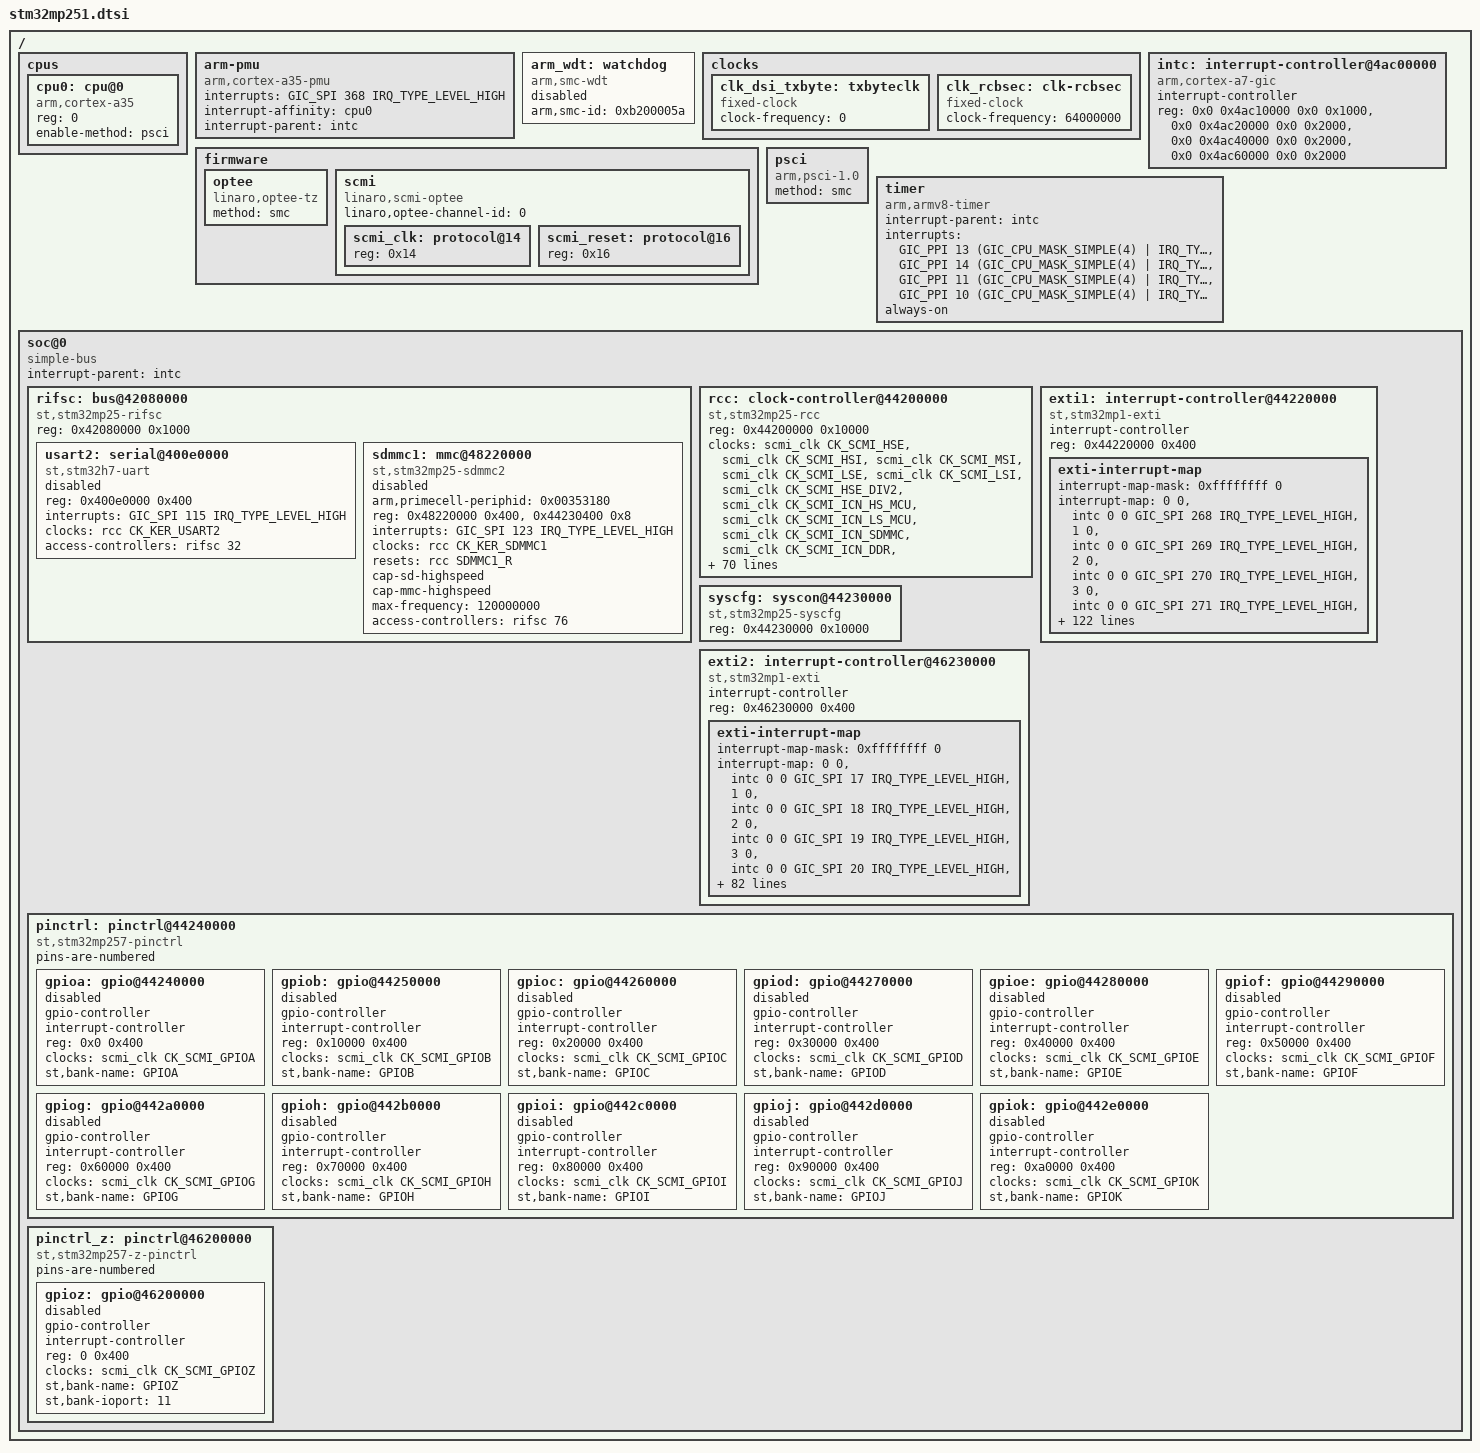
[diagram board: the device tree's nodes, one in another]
// SPDX-License-Identifier: (GPL-2.0-or-later OR BSD-3-Clause)
/*
 * Copyright (C) STMicroelectronics 2023 - All Rights Reserved
 * Author: Alexandre Torgue <alexandre.torgue@foss.st.com> for STMicroelectronics.
 */
#include <dt-bindings/clock/st,stm32mp25-rcc.h>
#include <dt-bindings/interrupt-controller/arm-gic.h>
#include <dt-bindings/reset/st,stm32mp25-rcc.h>

/ {
	#address-cells = <2>;
	#size-cells = <2>;

	cpus {
		#address-cells = <1>;
		#size-cells = <0>;

		cpu0: cpu@0 {
			compatible = "arm,cortex-a35";
			device_type = "cpu";
			reg = <0>;
			enable-method = "psci";
		};
	};

	arm-pmu {
		compatible = "arm,cortex-a35-pmu";
		interrupts = <GIC_SPI 368 IRQ_TYPE_LEVEL_HIGH>;
		interrupt-affinity = <&cpu0>;
		interrupt-parent = <&intc>;
	};

	arm_wdt: watchdog {
		compatible = "arm,smc-wdt";
		arm,smc-id = <0xb200005a>;
		status = "disabled";
	};

	clocks {
		clk_dsi_txbyte: txbyteclk {
			#clock-cells = <0>;
			compatible = "fixed-clock";
			clock-frequency = <0>;
		};

		clk_rcbsec: clk-rcbsec {
			#clock-cells = <0>;
			compatible = "fixed-clock";
			clock-frequency = <64000000>;
		};
	};

	firmware {
		optee {
			compatible = "linaro,optee-tz";
			method = "smc";
		};

		scmi {
			compatible = "linaro,scmi-optee";
			#address-cells = <1>;
			#size-cells = <0>;
			linaro,optee-channel-id = <0>;

			scmi_clk: protocol@14 {
				reg = <0x14>;
				#clock-cells = <1>;
			};

			scmi_reset: protocol@16 {
				reg = <0x16>;
				#reset-cells = <1>;
			};
		};
	};

	intc: interrupt-controller@4ac00000 {
		compatible = "arm,cortex-a7-gic";
		#interrupt-cells = <3>;
		#address-cells = <1>;
		interrupt-controller;
		reg = <0x0 0x4ac10000 0x0 0x1000>,
		      <0x0 0x4ac20000 0x0 0x2000>,
		      <0x0 0x4ac40000 0x0 0x2000>,
		      <0x0 0x4ac60000 0x0 0x2000>;
	};

	psci {
		compatible = "arm,psci-1.0";
		method = "smc";
	};

	timer {
		compatible = "arm,armv8-timer";
		interrupt-parent = <&intc>;
		interrupts = <GIC_PPI 13 (GIC_CPU_MASK_SIMPLE(4) | IRQ_TYPE_LEVEL_LOW)>,
			     <GIC_PPI 14 (GIC_CPU_MASK_SIMPLE(4) | IRQ_TYPE_LEVEL_LOW)>,
			     <GIC_PPI 11 (GIC_CPU_MASK_SIMPLE(4) | IRQ_TYPE_LEVEL_LOW)>,
			     <GIC_PPI 10 (GIC_CPU_MASK_SIMPLE(4) | IRQ_TYPE_LEVEL_LOW)>;
		always-on;
	};

	soc@0 {
		compatible = "simple-bus";
		#address-cells = <1>;
		#size-cells = <1>;
		interrupt-parent = <&intc>;
		ranges = <0x0 0x0 0x0 0x80000000>;

		rifsc: bus@42080000 {
			compatible = "st,stm32mp25-rifsc", "simple-bus";
			reg = <0x42080000 0x1000>;
			#address-cells = <1>;
			#size-cells = <1>;
			#access-controller-cells = <1>;
			ranges;

			usart2: serial@400e0000 {
				compatible = "st,stm32h7-uart";
				reg = <0x400e0000 0x400>;
				interrupts = <GIC_SPI 115 IRQ_TYPE_LEVEL_HIGH>;
				clocks = <&rcc CK_KER_USART2>;
				access-controllers = <&rifsc 32>;
				status = "disabled";
			};

			sdmmc1: mmc@48220000 {
				compatible = "st,stm32mp25-sdmmc2", "arm,pl18x", "arm,primecell";
				arm,primecell-periphid = <0x00353180>;
				reg = <0x48220000 0x400>, <0x44230400 0x8>;
				interrupts = <GIC_SPI 123 IRQ_TYPE_LEVEL_HIGH>;
				clocks = <&rcc CK_KER_SDMMC1>;
				clock-names = "apb_pclk";
				resets = <&rcc SDMMC1_R>;
				cap-sd-highspeed;
				cap-mmc-highspeed;
				max-frequency = <120000000>;
				access-controllers = <&rifsc 76>;
				status = "disabled";
			};
		};

		rcc: clock-controller@44200000 {
			compatible = "st,stm32mp25-rcc";
			reg = <0x44200000 0x10000>;
			#clock-cells = <1>;
			#reset-cells = <1>;
			clocks =
				<&scmi_clk CK_SCMI_HSE>,
				<&scmi_clk CK_SCMI_HSI>,
				<&scmi_clk CK_SCMI_MSI>,
				<&scmi_clk CK_SCMI_LSE>,
				<&scmi_clk CK_SCMI_LSI>,
				<&scmi_clk CK_SCMI_HSE_DIV2>,
				<&scmi_clk CK_SCMI_ICN_HS_MCU>,
				<&scmi_clk CK_SCMI_ICN_LS_MCU>,
				<&scmi_clk CK_SCMI_ICN_SDMMC>,
				<&scmi_clk CK_SCMI_ICN_DDR>,
				<&scmi_clk CK_SCMI_ICN_DISPLAY>,
				<&scmi_clk CK_SCMI_ICN_HSL>,
				<&scmi_clk CK_SCMI_ICN_NIC>,
				<&scmi_clk CK_SCMI_ICN_VID>,
				<&scmi_clk CK_SCMI_FLEXGEN_07>,
				<&scmi_clk CK_SCMI_FLEXGEN_08>,
				<&scmi_clk CK_SCMI_FLEXGEN_09>,
				<&scmi_clk CK_SCMI_FLEXGEN_10>,
				<&scmi_clk CK_SCMI_FLEXGEN_11>,
				<&scmi_clk CK_SCMI_FLEXGEN_12>,
				<&scmi_clk CK_SCMI_FLEXGEN_13>,
				<&scmi_clk CK_SCMI_FLEXGEN_14>,
				<&scmi_clk CK_SCMI_FLEXGEN_15>,
				<&scmi_clk CK_SCMI_FLEXGEN_16>,
				<&scmi_clk CK_SCMI_FLEXGEN_17>,
				<&scmi_clk CK_SCMI_FLEXGEN_18>,
				<&scmi_clk CK_SCMI_FLEXGEN_19>,
				<&scmi_clk CK_SCMI_FLEXGEN_20>,
				<&scmi_clk CK_SCMI_FLEXGEN_21>,
				<&scmi_clk CK_SCMI_FLEXGEN_22>,
				<&scmi_clk CK_SCMI_FLEXGEN_23>,
				<&scmi_clk CK_SCMI_FLEXGEN_24>,
				<&scmi_clk CK_SCMI_FLEXGEN_25>,
				<&scmi_clk CK_SCMI_FLEXGEN_26>,
				<&scmi_clk CK_SCMI_FLEXGEN_27>,
				<&scmi_clk CK_SCMI_FLEXGEN_28>,
				<&scmi_clk CK_SCMI_FLEXGEN_29>,
				<&scmi_clk CK_SCMI_FLEXGEN_30>,
				<&scmi_clk CK_SCMI_FLEXGEN_31>,
				<&scmi_clk CK_SCMI_FLEXGEN_32>,
				<&scmi_clk CK_SCMI_FLEXGEN_33>,
				<&scmi_clk CK_SCMI_FLEXGEN_34>,
				<&scmi_clk CK_SCMI_FLEXGEN_35>,
				<&scmi_clk CK_SCMI_FLEXGEN_36>,
				<&scmi_clk CK_SCMI_FLEXGEN_37>,
				<&scmi_clk CK_SCMI_FLEXGEN_38>,
				<&scmi_clk CK_SCMI_FLEXGEN_39>,
				<&scmi_clk CK_SCMI_FLEXGEN_40>,
				<&scmi_clk CK_SCMI_FLEXGEN_41>,
				<&scmi_clk CK_SCMI_FLEXGEN_42>,
				<&scmi_clk CK_SCMI_FLEXGEN_43>,
				<&scmi_clk CK_SCMI_FLEXGEN_44>,
				<&scmi_clk CK_SCMI_FLEXGEN_45>,
				<&scmi_clk CK_SCMI_FLEXGEN_46>,
				<&scmi_clk CK_SCMI_FLEXGEN_47>,
				<&scmi_clk CK_SCMI_FLEXGEN_48>,
				<&scmi_clk CK_SCMI_FLEXGEN_49>,
				<&scmi_clk CK_SCMI_FLEXGEN_50>,
				<&scmi_clk CK_SCMI_FLEXGEN_51>,
				<&scmi_clk CK_SCMI_FLEXGEN_52>,
				<&scmi_clk CK_SCMI_FLEXGEN_53>,
				<&scmi_clk CK_SCMI_FLEXGEN_54>,
				<&scmi_clk CK_SCMI_FLEXGEN_55>,
				<&scmi_clk CK_SCMI_FLEXGEN_56>,
				<&scmi_clk CK_SCMI_FLEXGEN_57>,
				<&scmi_clk CK_SCMI_FLEXGEN_58>,
				<&scmi_clk CK_SCMI_FLEXGEN_59>,
				<&scmi_clk CK_SCMI_FLEXGEN_60>,
				<&scmi_clk CK_SCMI_FLEXGEN_61>,
				<&scmi_clk CK_SCMI_FLEXGEN_62>,
				<&scmi_clk CK_SCMI_FLEXGEN_63>,
				<&scmi_clk CK_SCMI_ICN_APB1>,
				<&scmi_clk CK_SCMI_ICN_APB2>,
				<&scmi_clk CK_SCMI_ICN_APB3>,
				<&scmi_clk CK_SCMI_ICN_APB4>,
				<&scmi_clk CK_SCMI_ICN_APBDBG>,
				<&scmi_clk CK_SCMI_TIMG1>,
				<&scmi_clk CK_SCMI_TIMG2>,
				<&scmi_clk CK_SCMI_PLL3>,
				<&clk_dsi_txbyte>;
			access-controllers = <&rifsc 156>;
		};

		exti1: interrupt-controller@44220000 {
			compatible = "st,stm32mp1-exti", "syscon";
			interrupt-controller;
			#interrupt-cells = <2>;
			#address-cells = <0>;
			reg = <0x44220000 0x400>;

			exti-interrupt-map {
				#address-cells = <0>;
				#interrupt-cells = <2>;
				interrupt-map-mask = <0xffffffff 0>;
				interrupt-map =
					<0  0 &intc 0 0 GIC_SPI 268 IRQ_TYPE_LEVEL_HIGH>,
					<1  0 &intc 0 0 GIC_SPI 269 IRQ_TYPE_LEVEL_HIGH>,
					<2  0 &intc 0 0 GIC_SPI 270 IRQ_TYPE_LEVEL_HIGH>,
					<3  0 &intc 0 0 GIC_SPI 271 IRQ_TYPE_LEVEL_HIGH>,
					<4  0 &intc 0 0 GIC_SPI 272 IRQ_TYPE_LEVEL_HIGH>,
					<5  0 &intc 0 0 GIC_SPI 273 IRQ_TYPE_LEVEL_HIGH>,
					<6  0 &intc 0 0 GIC_SPI 274 IRQ_TYPE_LEVEL_HIGH>,
					<7  0 &intc 0 0 GIC_SPI 275 IRQ_TYPE_LEVEL_HIGH>,
					<8  0 &intc 0 0 GIC_SPI 276 IRQ_TYPE_LEVEL_HIGH>,
					<9  0 &intc 0 0 GIC_SPI 277 IRQ_TYPE_LEVEL_HIGH>,
					<10 0 &intc 0 0 GIC_SPI 278 IRQ_TYPE_LEVEL_HIGH>,
					<11 0 &intc 0 0 GIC_SPI 279 IRQ_TYPE_LEVEL_HIGH>,
					<12 0 &intc 0 0 GIC_SPI 280 IRQ_TYPE_LEVEL_HIGH>,
					<13 0 &intc 0 0 GIC_SPI 281 IRQ_TYPE_LEVEL_HIGH>,
					<14 0 &intc 0 0 GIC_SPI 282 IRQ_TYPE_LEVEL_HIGH>,
					<15 0 &intc 0 0 GIC_SPI 283 IRQ_TYPE_LEVEL_HIGH>,
					<16 0 &intc 0 0 GIC_SPI 0   IRQ_TYPE_LEVEL_HIGH>,
					<17 0 &intc 0 0 GIC_SPI 1   IRQ_TYPE_LEVEL_HIGH>,
					<18 0 &intc 0 0 GIC_SPI 260 IRQ_TYPE_LEVEL_HIGH>,
					<19 0 &intc 0 0 GIC_SPI 259 IRQ_TYPE_LEVEL_HIGH>,
					<21 0 &intc 0 0 GIC_SPI 108 IRQ_TYPE_LEVEL_HIGH>,
					<22 0 &intc 0 0 GIC_SPI 110 IRQ_TYPE_LEVEL_HIGH>,
					<23 0 &intc 0 0 GIC_SPI 137 IRQ_TYPE_LEVEL_HIGH>,
					<24 0 &intc 0 0 GIC_SPI 168 IRQ_TYPE_LEVEL_HIGH>,
					<25 0 &intc 0 0 GIC_SPI 181 IRQ_TYPE_LEVEL_HIGH>,
					<26 0 &intc 0 0 GIC_SPI 114 IRQ_TYPE_LEVEL_HIGH>,
					<27 0 &intc 0 0 GIC_SPI 115 IRQ_TYPE_LEVEL_HIGH>,
					<28 0 &intc 0 0 GIC_SPI 116 IRQ_TYPE_LEVEL_HIGH>,
					<29 0 &intc 0 0 GIC_SPI 136 IRQ_TYPE_LEVEL_HIGH>,
					<30 0 &intc 0 0 GIC_SPI 126 IRQ_TYPE_LEVEL_HIGH>,
					<31 0 &intc 0 0 GIC_SPI 127 IRQ_TYPE_LEVEL_HIGH>,
					<32 0 &intc 0 0 GIC_SPI 148 IRQ_TYPE_LEVEL_HIGH>,
					<33 0 &intc 0 0 GIC_SPI 149 IRQ_TYPE_LEVEL_HIGH>,
					<34 0 &intc 0 0 GIC_SPI 150 IRQ_TYPE_LEVEL_HIGH>,
					<36 0 &intc 0 0 GIC_SPI 112 IRQ_TYPE_LEVEL_HIGH>,
					<37 0 &intc 0 0 GIC_SPI 113 IRQ_TYPE_LEVEL_HIGH>,
					<38 0 &intc 0 0 GIC_SPI 125 IRQ_TYPE_LEVEL_HIGH>,
					<39 0 &intc 0 0 GIC_SPI 152 IRQ_TYPE_LEVEL_HIGH>,
					<40 0 &intc 0 0 GIC_SPI 153 IRQ_TYPE_LEVEL_HIGH>,
					<41 0 &intc 0 0 GIC_SPI 154 IRQ_TYPE_LEVEL_HIGH>,
					<42 0 &intc 0 0 GIC_SPI 155 IRQ_TYPE_LEVEL_HIGH>,
					<43 0 &intc 0 0 GIC_SPI 169 IRQ_TYPE_LEVEL_HIGH>,
					<44 0 &intc 0 0 GIC_SPI 182 IRQ_TYPE_LEVEL_HIGH>,
					<45 0 &intc 0 0 GIC_SPI 209 IRQ_TYPE_LEVEL_HIGH>,
					<46 0 &intc 0 0 GIC_SPI 229 IRQ_TYPE_LEVEL_HIGH>,
					<47 0 &intc 0 0 GIC_SPI 166 IRQ_TYPE_LEVEL_HIGH>,
					<48 0 &intc 0 0 GIC_SPI 215 IRQ_TYPE_LEVEL_HIGH>,
					<49 0 &intc 0 0 GIC_SPI 208 IRQ_TYPE_LEVEL_HIGH>,
					<50 0 &intc 0 0 GIC_SPI 210 IRQ_TYPE_LEVEL_HIGH>,
					<59 0 &intc 0 0 GIC_SPI 171 IRQ_TYPE_LEVEL_HIGH>,
					//	<59 0 &intc 0 0 GIC_SPI 172 IRQ_TYPE_LEVEL_HIGH>,
					<61 0 &intc 0 0 GIC_SPI 173 IRQ_TYPE_LEVEL_HIGH>,
					//	<61 0 &intc 0 0 GIC_SPI 174 IRQ_TYPE_LEVEL_HIGH>,
					<64 0 &intc 0 0 GIC_SPI 220 IRQ_TYPE_LEVEL_HIGH>,
					<67 0 &intc 0 0 GIC_SPI 10  IRQ_TYPE_LEVEL_HIGH>,
					<68 0 &intc 0 0 GIC_SPI 131 IRQ_TYPE_LEVEL_HIGH>,
					<70 0 &intc 0 0 GIC_SPI 134 IRQ_TYPE_LEVEL_HIGH>,
					<72 0 &intc 0 0 GIC_SPI 224 IRQ_TYPE_LEVEL_HIGH>,
					<73 0 &intc 0 0 GIC_SPI 202 IRQ_TYPE_LEVEL_HIGH>,
					<74 0 &intc 0 0 GIC_SPI 109 IRQ_TYPE_LEVEL_HIGH>,
					<75 0 &intc 0 0 GIC_SPI 111 IRQ_TYPE_LEVEL_HIGH>,
					<76 0 &intc 0 0 GIC_SPI 138 IRQ_TYPE_LEVEL_HIGH>,
					<77 0 &intc 0 0 GIC_SPI 253 IRQ_TYPE_LEVEL_HIGH>,
					<78 0 &intc 0 0 GIC_SPI 254 IRQ_TYPE_LEVEL_HIGH>,
					<79 0 &intc 0 0 GIC_SPI 255 IRQ_TYPE_LEVEL_HIGH>,
					<83 0 &intc 0 0 GIC_SPI 257 IRQ_TYPE_LEVEL_HIGH>,
					<84 0 &intc 0 0 GIC_SPI 258 IRQ_TYPE_LEVEL_HIGH>;
			};
		};

		syscfg: syscon@44230000 {
			compatible = "st,stm32mp25-syscfg", "syscon";
			reg = <0x44230000 0x10000>;
		};

		exti2: interrupt-controller@46230000 {
			compatible = "st,stm32mp1-exti", "syscon";
			interrupt-controller;
			#interrupt-cells = <2>;
			#address-cells = <0>;
			reg = <0x46230000 0x400>;

			exti-interrupt-map {
				#address-cells = <0>;
				#interrupt-cells = <2>;
				interrupt-map-mask = <0xffffffff 0>;
				interrupt-map =
					<0  0 &intc 0 0 GIC_SPI 17  IRQ_TYPE_LEVEL_HIGH>,
					<1  0 &intc 0 0 GIC_SPI 18  IRQ_TYPE_LEVEL_HIGH>,
					<2  0 &intc 0 0 GIC_SPI 19  IRQ_TYPE_LEVEL_HIGH>,
					<3  0 &intc 0 0 GIC_SPI 20  IRQ_TYPE_LEVEL_HIGH>,
					<4  0 &intc 0 0 GIC_SPI 21  IRQ_TYPE_LEVEL_HIGH>,
					<5  0 &intc 0 0 GIC_SPI 22  IRQ_TYPE_LEVEL_HIGH>,
					<6  0 &intc 0 0 GIC_SPI 23  IRQ_TYPE_LEVEL_HIGH>,
					<7  0 &intc 0 0 GIC_SPI 24  IRQ_TYPE_LEVEL_HIGH>,
					<8  0 &intc 0 0 GIC_SPI 25  IRQ_TYPE_LEVEL_HIGH>,
					<9  0 &intc 0 0 GIC_SPI 26  IRQ_TYPE_LEVEL_HIGH>,
					<10 0 &intc 0 0 GIC_SPI 27  IRQ_TYPE_LEVEL_HIGH>,
					<11 0 &intc 0 0 GIC_SPI 28  IRQ_TYPE_LEVEL_HIGH>,
					<12 0 &intc 0 0 GIC_SPI 29  IRQ_TYPE_LEVEL_HIGH>,
					<13 0 &intc 0 0 GIC_SPI 30  IRQ_TYPE_LEVEL_HIGH>,
					<14 0 &intc 0 0 GIC_SPI 31  IRQ_TYPE_LEVEL_HIGH>,
					<15 0 &intc 0 0 GIC_SPI 32  IRQ_TYPE_LEVEL_HIGH>,
					<16 0 &intc 0 0 GIC_SPI 12  IRQ_TYPE_LEVEL_HIGH>,
					<17 0 &intc 0 0 GIC_SPI 13  IRQ_TYPE_LEVEL_HIGH>,
					<21 0 &intc 0 0 GIC_SPI 14  IRQ_TYPE_LEVEL_HIGH>,
					<22 0 &intc 0 0 GIC_SPI 15  IRQ_TYPE_LEVEL_HIGH>,
					<25 0 &intc 0 0 GIC_SPI 212 IRQ_TYPE_LEVEL_HIGH>,
					<26 0 &intc 0 0 GIC_SPI 151 IRQ_TYPE_LEVEL_HIGH>,
					<27 0 &intc 0 0 GIC_SPI 156 IRQ_TYPE_LEVEL_HIGH>,
					<29 0 &intc 0 0 GIC_SPI 216 IRQ_TYPE_LEVEL_HIGH>,
					<30 0 &intc 0 0 GIC_SPI 217 IRQ_TYPE_LEVEL_HIGH>,
					<31 0 &intc 0 0 GIC_SPI 218 IRQ_TYPE_LEVEL_HIGH>,
					<33 0 &intc 0 0 GIC_SPI 207 IRQ_TYPE_LEVEL_HIGH>,
					<34 0 &intc 0 0 GIC_SPI 175 IRQ_TYPE_LEVEL_HIGH>,
					//	<34 0 &intc 0 0 GIC_SPI 176 IRQ_TYPE_LEVEL_HIGH>,
					<37 0 &intc 0 0 GIC_SPI 177 IRQ_TYPE_LEVEL_HIGH>,
					//	<37 0 &intc 0 0 GIC_SPI 178 IRQ_TYPE_LEVEL_HIGH>,
					<40 0 &intc 0 0 GIC_SPI 199 IRQ_TYPE_LEVEL_HIGH>,
					<43 0 &intc 0 0 GIC_SPI 200 IRQ_TYPE_LEVEL_HIGH>,
					<46 0 &intc 0 0 GIC_SPI 11  IRQ_TYPE_LEVEL_HIGH>,
					<48 0 &intc 0 0 GIC_SPI 5   IRQ_TYPE_LEVEL_HIGH>,
					<49 0 &intc 0 0 GIC_SPI 4   IRQ_TYPE_LEVEL_HIGH>,
					<50 0 &intc 0 0 GIC_SPI 6   IRQ_TYPE_LEVEL_HIGH>,
					<51 0 &intc 0 0 GIC_SPI 7   IRQ_TYPE_LEVEL_HIGH>,
					<52 0 &intc 0 0 GIC_SPI 2   IRQ_TYPE_LEVEL_HIGH>,
					<53 0 &intc 0 0 GIC_SPI 3   IRQ_TYPE_LEVEL_HIGH>,
					<61 0 &intc 0 0 GIC_SPI 221 IRQ_TYPE_LEVEL_HIGH>,
					<62 0 &intc 0 0 GIC_SPI 246 IRQ_TYPE_LEVEL_HIGH>,
					<64 0 &intc 0 0 GIC_SPI 247 IRQ_TYPE_LEVEL_HIGH>,
					<65 0 &intc 0 0 GIC_SPI 248 IRQ_TYPE_LEVEL_HIGH>,
					<66 0 &intc 0 0 GIC_SPI 249 IRQ_TYPE_LEVEL_HIGH>,
					<67 0 &intc 0 0 GIC_SPI 256 IRQ_TYPE_LEVEL_HIGH>,
					<70 0 &intc 0 0 GIC_SPI 213 IRQ_TYPE_LEVEL_HIGH>;
			};
		};

		/* Break node order to solve dependency probe issue between pinctrl and exti. */

		pinctrl: pinctrl@44240000 {
			#address-cells = <1>;
			#size-cells = <1>;
			compatible = "st,stm32mp257-pinctrl";
			ranges = <0 0x44240000 0xa0400>;
			pins-are-numbered;

			gpioa: gpio@44240000 {
				gpio-controller;
				#gpio-cells = <2>;
				interrupt-controller;
				#interrupt-cells = <2>;
				reg = <0x0 0x400>;
				clocks = <&scmi_clk CK_SCMI_GPIOA>;
				st,bank-name = "GPIOA";
				status = "disabled";
			};

			gpiob: gpio@44250000 {
				gpio-controller;
				#gpio-cells = <2>;
				interrupt-controller;
				#interrupt-cells = <2>;
				reg = <0x10000 0x400>;
				clocks = <&scmi_clk CK_SCMI_GPIOB>;
				st,bank-name = "GPIOB";
				status = "disabled";
			};

			gpioc: gpio@44260000 {
				gpio-controller;
				#gpio-cells = <2>;
				interrupt-controller;
				#interrupt-cells = <2>;
				reg = <0x20000 0x400>;
				clocks = <&scmi_clk CK_SCMI_GPIOC>;
				st,bank-name = "GPIOC";
				status = "disabled";
			};

			gpiod: gpio@44270000 {
				gpio-controller;
				#gpio-cells = <2>;
				interrupt-controller;
				#interrupt-cells = <2>;
				reg = <0x30000 0x400>;
				clocks = <&scmi_clk CK_SCMI_GPIOD>;
				st,bank-name = "GPIOD";
				status = "disabled";
			};

			gpioe: gpio@44280000 {
				gpio-controller;
				#gpio-cells = <2>;
				interrupt-controller;
				#interrupt-cells = <2>;
				reg = <0x40000 0x400>;
				clocks = <&scmi_clk CK_SCMI_GPIOE>;
				st,bank-name = "GPIOE";
				status = "disabled";
			};

			gpiof: gpio@44290000 {
				gpio-controller;
				#gpio-cells = <2>;
				interrupt-controller;
				#interrupt-cells = <2>;
				reg = <0x50000 0x400>;
				clocks = <&scmi_clk CK_SCMI_GPIOF>;
				st,bank-name = "GPIOF";
				status = "disabled";
			};

			gpiog: gpio@442a0000 {
				gpio-controller;
				#gpio-cells = <2>;
				interrupt-controller;
				#interrupt-cells = <2>;
				reg = <0x60000 0x400>;
				clocks = <&scmi_clk CK_SCMI_GPIOG>;
				st,bank-name = "GPIOG";
				status = "disabled";
			};

			gpioh: gpio@442b0000 {
				gpio-controller;
				#gpio-cells = <2>;
				interrupt-controller;
				#interrupt-cells = <2>;
				reg = <0x70000 0x400>;
				clocks = <&scmi_clk CK_SCMI_GPIOH>;
				st,bank-name = "GPIOH";
				status = "disabled";
			};

			gpioi: gpio@442c0000 {
				gpio-controller;
				#gpio-cells = <2>;
				interrupt-controller;
				#interrupt-cells = <2>;
				reg = <0x80000 0x400>;
				clocks = <&scmi_clk CK_SCMI_GPIOI>;
				st,bank-name = "GPIOI";
				status = "disabled";
			};

			gpioj: gpio@442d0000 {
				gpio-controller;
				#gpio-cells = <2>;
				interrupt-controller;
				#interrupt-cells = <2>;
				reg = <0x90000 0x400>;
				clocks = <&scmi_clk CK_SCMI_GPIOJ>;
				st,bank-name = "GPIOJ";
				status = "disabled";
			};

			gpiok: gpio@442e0000 {
				gpio-controller;
				#gpio-cells = <2>;
				interrupt-controller;
				#interrupt-cells = <2>;
				reg = <0xa0000 0x400>;
				clocks = <&scmi_clk CK_SCMI_GPIOK>;
				st,bank-name = "GPIOK";
				status = "disabled";
			};
		};

		pinctrl_z: pinctrl@46200000 {
			#address-cells = <1>;
			#size-cells = <1>;
			compatible = "st,stm32mp257-z-pinctrl";
			ranges = <0 0x46200000 0x400>;
			pins-are-numbered;

			gpioz: gpio@46200000 {
				gpio-controller;
				#gpio-cells = <2>;
				interrupt-controller;
				#interrupt-cells = <2>;
				reg = <0 0x400>;
				clocks = <&scmi_clk CK_SCMI_GPIOZ>;
				st,bank-name = "GPIOZ";
				st,bank-ioport = <11>;
				status = "disabled";
			};
		};
	};
};
